# MKE18F16 register map
Vendor: Freescale Semiconductor, Inc.; Series: Kinetis_E; File version: 1.6
CPU: CM4 r0p1, little endian, no MPU, FPU, VTOR, 4 interrupt priority bits
Registers are 32-bit, read-write, reset 0x0 unless marked. A register's access mark holds for its fields unless they carry their own. Offsets are from the block's base; [hi:lo] are bit positions; {n}, {i} and the like mark numbered series; 'fields as' and 'values as' point back to an identical list.

## CAN0 — Flex Controller Area Network module
Base 0x40024000; register names take the prefix CAN0_
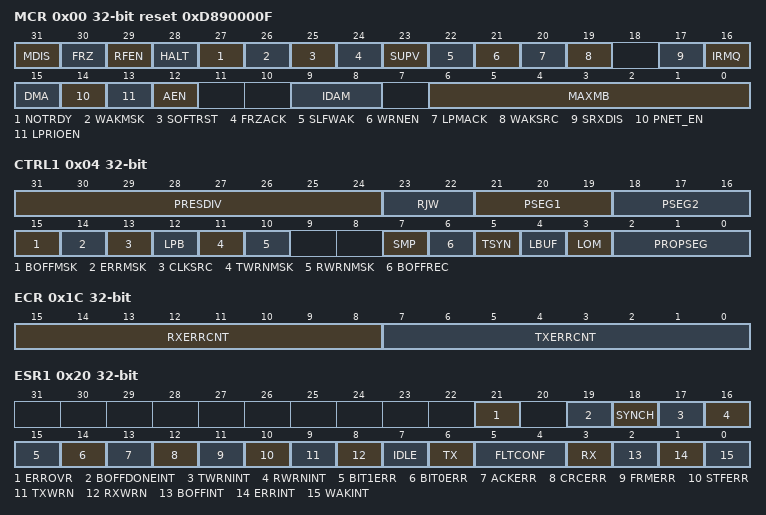
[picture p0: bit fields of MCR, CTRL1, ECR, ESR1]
0x00 MCR reset 0xD890000F — Module Configuration Register
  [31] MDIS — Module Disable
    0=Enable the FlexCAN module; 1=Disable the FlexCAN module
  [30] FRZ — Freeze Enable
    0=Not enabled to enter Freeze mode; 1=Enabled to enter Freeze mode
  [29] RFEN — Rx FIFO Enable
    0=Rx FIFO not enabled; 1=Rx FIFO enabled
  [28] HALT — Halt FlexCAN
    0=No Freeze mode request; 1=Enters Freeze mode if the FRZ bit is asserted
  [27] NOTRDY ro — FlexCAN Not Ready
    0=FlexCAN module is either in Normal mode, Listen-Only mode or Loop-Back mode; 1=FlexCAN module is either in Disable mode, Stop mode or Freeze mode
  [26] WAKMSK — Wake Up Interrupt Mask
    0=Wake Up Interrupt is disabled; 1=Wake Up Interrupt is enabled
  [25] SOFTRST — Soft Reset
    0=No reset request; 1=Resets the registers affected by soft reset
  [24] FRZACK ro — Freeze Mode Acknowledge
    0=FlexCAN not in Freeze mode, prescaler running; 1=FlexCAN in Freeze mode, prescaler stopped
  [23] SUPV — Supervisor Mode
    0=FlexCAN is in User mode. Affected registers allow both Supervisor and Unrestricted accesses.; 1=FlexCAN is in Supervisor mode. Affected registers allow only Supervisor access. Unrestricted access behaves as though the access was done to an unimplemented register location.
  [22] SLFWAK — Self Wake Up
    0=FlexCAN Self Wake Up feature is disabled; 1=FlexCAN Self Wake Up feature is enabled
  [21] WRNEN — Warning Interrupt Enable
    0=TWRNINT and RWRNINT bits are zero, independent of the values in the error counters; 1=TWRNINT and RWRNINT bits are set when the respective error counter transitions from less than 96 to greater than or equal to 96
  [20] LPMACK ro — Low-Power Mode Acknowledge
    0=FlexCAN is not in a low-power mode; 1=FlexCAN is in a low-power mode
  [19] WAKSRC — Wake Up Source
    0=FlexCAN uses the unfiltered Rx input to detect recessive to dominant edges on the CAN bus; 1=FlexCAN uses the filtered Rx input to detect recessive to dominant edges on the CAN bus
  [17] SRXDIS — Self Reception Disable
    0=Self reception enabled; 1=Self reception disabled
  [16] IRMQ — Individual Rx Masking And Queue Enable
    0=Individual Rx masking and queue feature are disabled. For backward compatibility with legacy applications, the reading of C/S word locks the MB even if it is EMPTY.; 1=Individual Rx masking and queue feature are enabled
  [15] DMA — DMA Enable
    0=DMA feature for RX FIFO disabled; 1=DMA feature for RX FIFO enabled
  [14] PNET_EN — Pretended Networking Enable
    0=Pretended Networking mode is disabled; 1=Pretended Networking mode is enabled
  [13] LPRIOEN — Local Priority Enable
    0=Local Priority disabled; 1=Local Priority enabled
  [12] AEN — Abort Enable
    0=Abort disabled; 1=Abort enabled
  [9:8] IDAM — ID Acceptance Mode
    0=Format A: One full ID (standard and extended) per ID Filter Table element; 1=Format B: Two full standard IDs or two partial 14-bit (standard and extended) IDs per ID Filter Table element; 2=Format C: Four partial 8-bit Standard IDs per ID Filter Table element; 3=Format D: All frames rejected
  [6:0] MAXMB — Number Of The Last Message Buffer
0x04 CTRL1 — Control 1 register
  [31:24] PRESDIV — Prescaler Division Factor
  [23:22] RJW — Resync Jump Width
  [21:19] PSEG1 — Phase Segment 1
  [18:16] PSEG2 — Phase Segment 2
  [15] BOFFMSK — Bus Off Interrupt Mask
    0=Bus Off interrupt disabled; 1=Bus Off interrupt enabled
  [14] ERRMSK — Error Interrupt Mask
    0=Error interrupt disabled; 1=Error interrupt enabled
  [13] CLKSRC — CAN Engine Clock Source
    0=The CAN engine clock source is the oscillator clock. Under this condition, the oscillator clock frequency must be lower than the bus clock.; 1=The CAN engine clock source is the peripheral clock
  [12] LPB — Loop Back Mode
    0=Loop Back disabled; 1=Loop Back enabled
  [11] TWRNMSK — Tx Warning Interrupt Mask
    0=Tx Warning Interrupt disabled; 1=Tx Warning Interrupt enabled
  [10] RWRNMSK — Rx Warning Interrupt Mask
    0=Rx Warning Interrupt disabled; 1=Rx Warning Interrupt enabled
  [7] SMP — CAN Bit Sampling
    0=Just one sample is used to determine the bit value; 1=Three samples are used to determine the value of the received bit: the regular one (sample point) and 2 preceding samples; a majority rule is used
  [6] BOFFREC — Bus Off Recovery
    0=Automatic recovering from Bus Off state enabled; 1=Automatic recovering from Bus Off state disabled
  [5] TSYN — Timer Sync
    0=Timer Sync feature disabled; 1=Timer Sync feature enabled
  [4] LBUF — Lowest Buffer Transmitted First
    0=Buffer with highest priority is transmitted first; 1=Lowest number buffer is transmitted first
  [3] LOM — Listen-Only Mode
    0=Listen-Only mode is deactivated; 1=FlexCAN module operates in Listen-Only mode
  [2:0] PROPSEG — Propagation Segment
0x08 TIMER — Free Running Timer
  [15:0] TIMER — Timer Value
0x10 RXMGMASK reset not defined — Rx Mailboxes Global Mask Register
  [31:0] MG — Rx Mailboxes Global Mask Bits
    0=The corresponding bit in the filter is "don't care."; 1=The corresponding bit in the filter is checked
0x14 RX14MASK reset not defined
  [31:0] RX14M — Rx Buffer 14 Mask Bits
    values as RXMGMASK.MG
0x18 RX15MASK reset not defined
  [31:0] RX15M — Rx Buffer 15 Mask Bits
    values as RXMGMASK.MG
0x1C ECR — Error Counter
  [15:8] RXERRCNT — Receive Error Counter
  [7:0] TXERRCNT — Transmit Error Counter
0x20 ESR1 — Error and Status 1 register
  [21] ERROVR — Error Overrun bit
    0=Overrun has not occurred; 1=Overrun has occured
  [19] BOFFDONEINT — Bus Off Done Interrupt
    0=No such occurrence; 1=FlexCAN module has completed Bus Off process
  [18] SYNCH ro — CAN Synchronization Status
    0=FlexCAN is not synchronized to the CAN bus; 1=FlexCAN is synchronized to the CAN bus
  [17] TWRNINT — Tx Warning Interrupt Flag
    0=No such occurrence; 1=The Tx error counter transitioned from less than 96 to greater than or equal to 96
  [16] RWRNINT — Rx Warning Interrupt Flag
    0=No such occurrence; 1=The Rx error counter transitioned from less than 96 to greater than or equal to 96
  [15] BIT1ERR ro — Bit1 Error
    0=No such occurrence; 1=At least one bit sent as recessive is received as dominant
  [14] BIT0ERR ro — Bit0 Error
    0=No such occurrence; 1=At least one bit sent as dominant is received as recessive
  [13] ACKERR ro — Acknowledge Error
    0=No such occurrence; 1=An ACK error occurred since last read of this register
  [12] CRCERR ro — Cyclic Redundancy Check Error
    0=No such occurrence; 1=A CRC error occurred since last read of this register
  [11] FRMERR ro — Form Error
    0=No such occurrence; 1=A Form Error occurred since last read of this register
  [10] STFERR ro — Stuffing Error
    0=No such occurrence; 1=A Stuffing Error occurred since last read of this register
  [9] TXWRN ro — TX Error Warning
    0=No such occurrence; 1=TXERRCNT is greater than or equal to 96
  [8] RXWRN ro — Rx Error Warning
    0=No such occurrence; 1=RXERRCNT is greater than or equal to 96
  [7] IDLE ro — This bit indicates when CAN bus is in IDLE state
    0=No such occurrence; 1=CAN bus is now IDLE
  [6] TX ro — FlexCAN In Transmission
    0=FlexCAN is not transmitting a message; 1=FlexCAN is transmitting a message
  [5:4] FLTCONF ro — Fault Confinement State
    0=Error Active; 1=Error Passive; 0b1x=Bus Off
  [3] RX ro — FlexCAN In Reception
    0=FlexCAN is not receiving a message; 1=FlexCAN is receiving a message
  [2] BOFFINT — Bus Off Interrupt
    0=No such occurrence; 1=FlexCAN module entered Bus Off state
  [1] ERRINT — Error Interrupt
    0=No such occurrence; 1=Indicates setting of any Error Bit in the Error and Status Register
  [0] WAKINT — Wake-Up Interrupt
    0=No such occurrence; 1=Indicates a recessive to dominant transition was received on the CAN bus
0x28 IMASK1 — Interrupt Masks 1 register
  [31:0] BUF31TO0M — Buffer MB i Mask
    0=The corresponding buffer Interrupt is disabled; 1=The corresponding buffer Interrupt is enabled
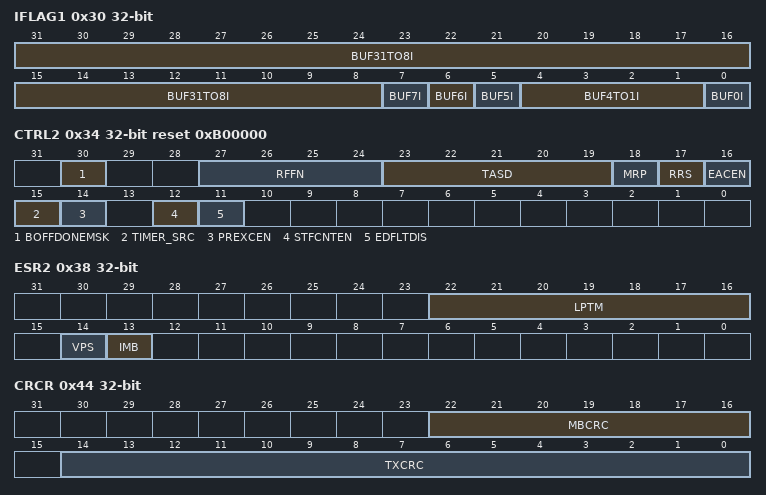
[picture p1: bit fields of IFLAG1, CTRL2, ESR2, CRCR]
0x30 IFLAG1 — Interrupt Flags 1 register
  [31:8] BUF31TO8I — Buffer MBi Interrupt
    0=The corresponding buffer has no occurrence of successfully completed transmission or reception; 1=The corresponding buffer has successfully completed transmission or reception
  [7] BUF7I — Buffer MB7 Interrupt Or "Rx FIFO Overflow"
    0=No occurrence of MB7 completing transmission/reception when MCR[RFEN]=0, or of Rx FIFO overflow when MCR[RFEN]=1; 1=MB7 completed transmission/reception when MCR[RFEN]=0, or Rx FIFO overflow when MCR[RFEN]=1
  [6] BUF6I — Buffer MB6 Interrupt Or "Rx FIFO Warning"
    0=No occurrence of MB6 completing transmission/reception when MCR[RFEN]=0, or of Rx FIFO almost full when MCR[RFEN]=1; 1=MB6 completed transmission/reception when MCR[RFEN]=0, or Rx FIFO almost full when MCR[RFEN]=1
  [5] BUF5I — Buffer MB5 Interrupt Or "Frames available in Rx FIFO"
    0=No occurrence of MB5 completing transmission/reception when MCR[RFEN]=0, or of frame(s) available in the FIFO, when MCR[RFEN]=1; 1=MB5 completed transmission/reception when MCR[RFEN]=0, or frame(s) available in the Rx FIFO when MCR[RFEN]=1. It generates a DMA request in case of MCR[RFEN] and MCR[DMA] are enabled.
  [4:1] BUF4TO1I — Buffer MB i Interrupt Or "reserved"
    0=The corresponding buffer has no occurrence of successfully completed transmission or reception when MCR[RFEN]=0; 1=The corresponding buffer has successfully completed transmission or reception when MCR[RFEN]=0
  [0] BUF0I — Buffer MB0 Interrupt Or Clear FIFO bit
    values as BUF4TO1I
0x34 CTRL2 reset 0xB00000 — Control 2 register
  [30] BOFFDONEMSK — Bus Off Done Interrupt Mask
    0=Bus Off Done interrupt disabled; 1=Bus Off Done interrupt enabled
  [27:24] RFFN — Number Of Rx FIFO Filters
  [23:19] TASD — Tx Arbitration Start Delay
  [18] MRP — Mailboxes Reception Priority
    0=Matching starts from Rx FIFO and continues on Mailboxes; 1=Matching starts from Mailboxes and continues on Rx FIFO
  [17] RRS — Remote Request Storing
    0=Remote Response Frame is generated; 1=Remote Request Frame is stored
  [16] EACEN — Entire Frame Arbitration Field Comparison Enable For Rx Mailboxes
    0=Rx Mailbox filter's IDE bit is always compared and RTR is never compared despite mask bits; 1=Enables the comparison of both Rx Mailbox filter's IDE and RTR bit with their corresponding bits within the incoming frame. Mask bits do apply.
  [15] TIMER_SRC — Timer Source
    0=The Free Running Timer is clocked by the CAN bit clock, which defines the baud rate on the CAN bus; 1=The Free Running Timer is clocked by an external time tick. The period can be either adjusted to be equal to the baud rate on the CAN bus, or a different value as required. See the device specific section for details about the external time tick.
  [14] PREXCEN — Protocol Exception Enable
    0=Protocol Exception is disabled; 1=Protocol Exception is enabled
  [12] STFCNTEN — Stuff Count Enable
    0=Stuff Count feature is disabled. Stuff Count bit field is not inserted before the CRC Sequence field.; 1=Stuff Count feature is enabled. Stuff Count bit field is inserted before the CRC Sequence field.
  [11] EDFLTDIS — Edge Filter Disable
    0=Edge Filter is enabled; 1=Edge Filter is disabled
0x38 ESR2 ro — Error and Status 2 register
  [22:16] LPTM — Lowest Priority Tx Mailbox
  [14] VPS — Valid Priority Status
    0=Contents of IMB and LPTM are invalid; 1=Contents of IMB and LPTM are valid
  [13] IMB — Inactive Mailbox
    0=If ESR2[VPS] is asserted, the ESR2[LPTM] is not an inactive Mailbox; 1=If ESR2[VPS] is asserted, there is at least one inactive Mailbox. LPTM content is the number of the first one.
0x44 CRCR ro — CRC Register
  [22:16] MBCRC — CRC Mailbox
  [14:0] TXCRC — Transmitted CRC value
0x48 RXFGMASK reset not defined — Rx FIFO Global Mask register
  [31:0] FGM — Rx FIFO Global Mask Bits
    values as RXMGMASK.MG
0x4C RXFIR ro reset not defined — Rx FIFO Information Register
  [8:0] IDHIT — Identifier Acceptance Filter Hit Indicator
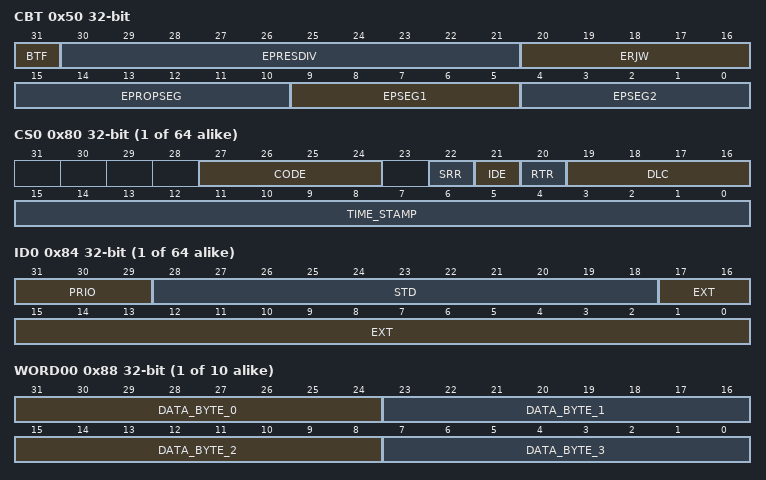
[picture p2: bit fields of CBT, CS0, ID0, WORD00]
0x50 CBT — CAN Bit Timing Register
  [31] BTF — Bit Timing Format Enable
    0=Extended bit time definitions disabled; 1=Extended bit time definitions enabled
  [30:21] EPRESDIV — Extended Prescaler Division Factor
  [20:16] ERJW — Extended Resync Jump Width
  [15:10] EPROPSEG — Extended Propagation Segment
  [9:5] EPSEG1 — Extended Phase Segment 1
  [4:0] EPSEG2 — Extended Phase Segment 2
{0x80+0x10*i} CS{i} (i=0..63) — Message Buffer {i} CS Register
  [27:24] CODE — Reserved
  [22] SRR — Substitute Remote Request. Contains a fixed recessive bit.
  [21] IDE — ID Extended. One/zero for extended/standard format frame.
  [20] RTR — Remote Transmission Request. One/zero for remote/data frame.
  [19:16] DLC — Length of the data to be stored/transmitted.
  [15:0] TIME_STAMP — Free-Running Counter Time stamp. This 16-bit field is a copy of the Free-Running Timer, captured for Tx and Rx frames at the time when the beginning of the Identifier field appears on the CAN bus.
{0x84+0x10*i} ID{i} (i=0..63) — Message Buffer {i} ID Register
  [31:29] PRIO — Local priority. This 3-bit fieldis only used when LPRIO_EN bit is set in MCR and it only makes sense for Tx buffers. These bits are not transmitted. They are appended to the regular ID to define the transmission priority.
  [28:18] STD — Contains standard/extended (HIGH word) identifier of message buffer.
  [17:0] EXT — Contains extended (LOW word) identifier of message buffer.
{0x88+0x10*i} WORD{i:02} (i=0..9) — Message Buffer {i} WORD0 Register
  [31-8n:24-8n] DATA_BYTE_{n} (n=0..3) — Data byte {n} of Rx/Tx frame.
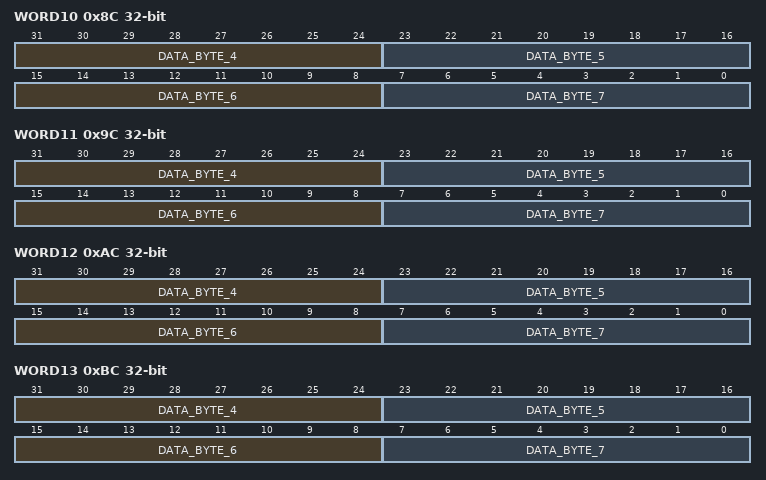
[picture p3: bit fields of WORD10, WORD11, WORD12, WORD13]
0x8C WORD10 — Message Buffer 0 WORD1 Register
  [63-8n:56-8n] DATA_BYTE_{n} (n=4..7) — Data byte {n} of Rx/Tx frame.
0x9C WORD11 — Message Buffer 1 WORD1 Register
  [63-8n:56-8n] DATA_BYTE_{n} (n=4..7) — Data byte {n} of Rx/Tx frame.
0xAC WORD12 — Message Buffer 2 WORD1 Register
  [63-8n:56-8n] DATA_BYTE_{n} (n=4..7) — Data byte {n} of Rx/Tx frame.
0xBC WORD13 — Message Buffer 3 WORD1 Register
  [63-8n:56-8n] DATA_BYTE_{n} (n=4..7) — Data byte {n} of Rx/Tx frame.
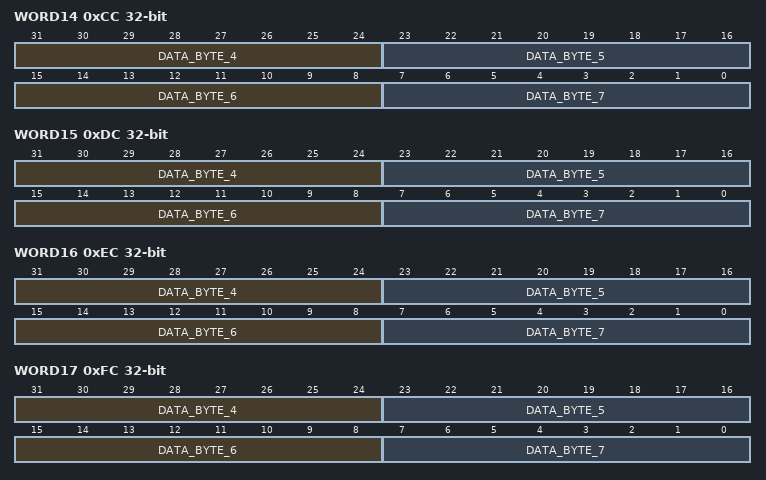
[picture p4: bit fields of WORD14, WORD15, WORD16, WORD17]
0xCC WORD14 — Message Buffer 4 WORD1 Register
  [63-8n:56-8n] DATA_BYTE_{n} (n=4..7) — Data byte {n} of Rx/Tx frame.
0xDC WORD15 — Message Buffer 5 WORD1 Register
  [63-8n:56-8n] DATA_BYTE_{n} (n=4..7) — Data byte {n} of Rx/Tx frame.
0xEC WORD16 — Message Buffer 6 WORD1 Register
  [63-8n:56-8n] DATA_BYTE_{n} (n=4..7) — Data byte {n} of Rx/Tx frame.
0xFC WORD17 — Message Buffer 7 WORD1 Register
  [63-8n:56-8n] DATA_BYTE_{n} (n=4..7) — Data byte {n} of Rx/Tx frame.
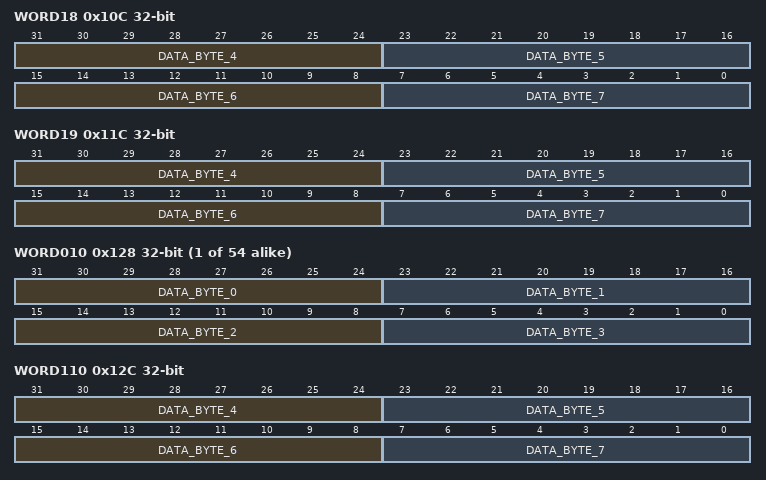
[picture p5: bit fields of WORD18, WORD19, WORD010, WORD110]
0x10C WORD18 — Message Buffer 8 WORD1 Register
  [63-8n:56-8n] DATA_BYTE_{n} (n=4..7) — Data byte {n} of Rx/Tx frame.
0x11C WORD19 — Message Buffer 9 WORD1 Register
  [63-8n:56-8n] DATA_BYTE_{n} (n=4..7) — Data byte {n} of Rx/Tx frame.
{0x88+0x10*i} WORD{i:03} (i=10..63) — Message Buffer {i} WORD0 Register
  [31-8n:24-8n] DATA_BYTE_{n} (n=0..3) — Data byte {n} of Rx/Tx frame.
0x12C WORD110 — Message Buffer 10 WORD1 Register
  [63-8n:56-8n] DATA_BYTE_{n} (n=4..7) — Data byte {n} of Rx/Tx frame.
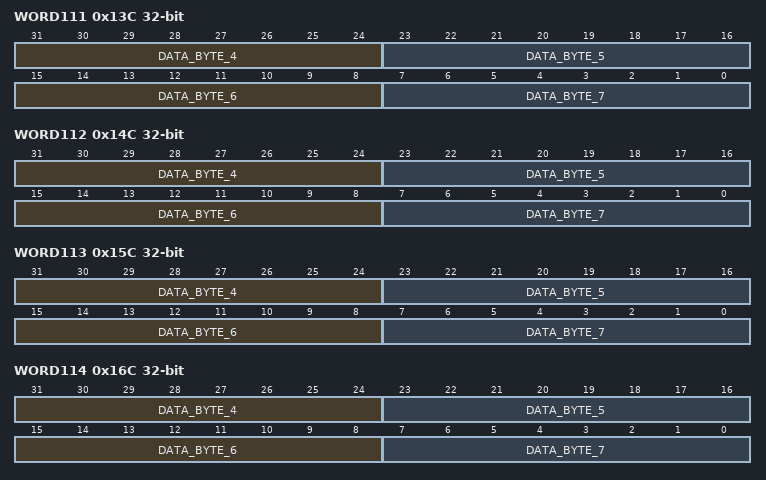
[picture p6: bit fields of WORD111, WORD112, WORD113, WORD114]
0x13C WORD111 — Message Buffer 11 WORD1 Register
  [63-8n:56-8n] DATA_BYTE_{n} (n=4..7) — Data byte {n} of Rx/Tx frame.
0x14C WORD112 — Message Buffer 12 WORD1 Register
  [63-8n:56-8n] DATA_BYTE_{n} (n=4..7) — Data byte {n} of Rx/Tx frame.
0x15C WORD113 — Message Buffer 13 WORD1 Register
  [63-8n:56-8n] DATA_BYTE_{n} (n=4..7) — Data byte {n} of Rx/Tx frame.
0x16C WORD114 — Message Buffer 14 WORD1 Register
  [63-8n:56-8n] DATA_BYTE_{n} (n=4..7) — Data byte {n} of Rx/Tx frame.
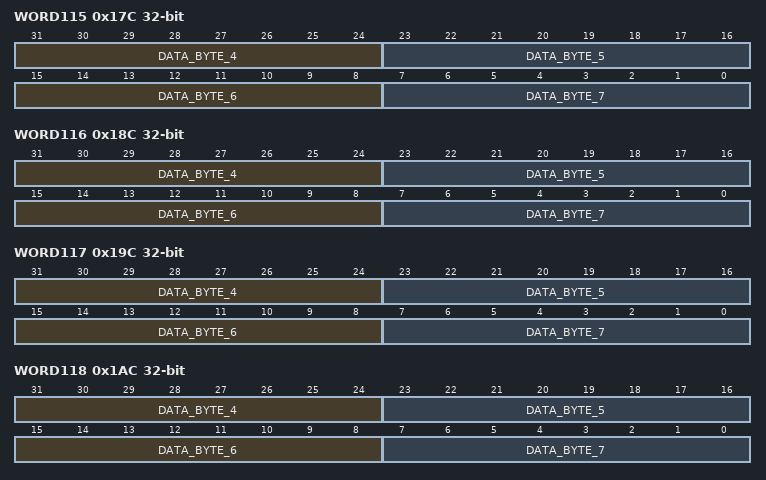
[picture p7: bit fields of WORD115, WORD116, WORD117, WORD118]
0x17C WORD115 — Message Buffer 15 WORD1 Register
  [63-8n:56-8n] DATA_BYTE_{n} (n=4..7) — Data byte {n} of Rx/Tx frame.
0x18C WORD116 — Message Buffer 16 WORD1 Register
  [63-8n:56-8n] DATA_BYTE_{n} (n=4..7) — Data byte {n} of Rx/Tx frame.
0x19C WORD117 — Message Buffer 17 WORD1 Register
  [63-8n:56-8n] DATA_BYTE_{n} (n=4..7) — Data byte {n} of Rx/Tx frame.
0x1AC WORD118 — Message Buffer 18 WORD1 Register
  [63-8n:56-8n] DATA_BYTE_{n} (n=4..7) — Data byte {n} of Rx/Tx frame.
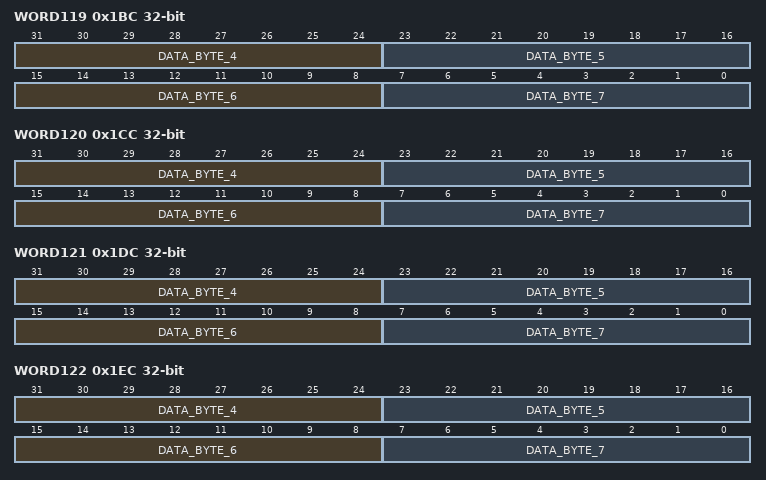
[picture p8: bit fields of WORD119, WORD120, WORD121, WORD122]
0x1BC WORD119 — Message Buffer 19 WORD1 Register
  [63-8n:56-8n] DATA_BYTE_{n} (n=4..7) — Data byte {n} of Rx/Tx frame.
0x1CC WORD120 — Message Buffer 20 WORD1 Register
  [63-8n:56-8n] DATA_BYTE_{n} (n=4..7) — Data byte {n} of Rx/Tx frame.
0x1DC WORD121 — Message Buffer 21 WORD1 Register
  [63-8n:56-8n] DATA_BYTE_{n} (n=4..7) — Data byte {n} of Rx/Tx frame.
0x1EC WORD122 — Message Buffer 22 WORD1 Register
  [63-8n:56-8n] DATA_BYTE_{n} (n=4..7) — Data byte {n} of Rx/Tx frame.
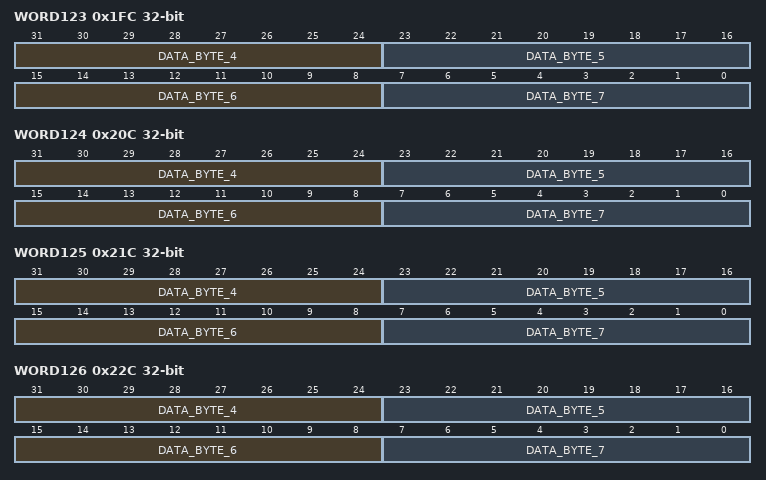
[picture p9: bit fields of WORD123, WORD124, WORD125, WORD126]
0x1FC WORD123 — Message Buffer 23 WORD1 Register
  [63-8n:56-8n] DATA_BYTE_{n} (n=4..7) — Data byte {n} of Rx/Tx frame.
0x20C WORD124 — Message Buffer 24 WORD1 Register
  [63-8n:56-8n] DATA_BYTE_{n} (n=4..7) — Data byte {n} of Rx/Tx frame.
0x21C WORD125 — Message Buffer 25 WORD1 Register
  [63-8n:56-8n] DATA_BYTE_{n} (n=4..7) — Data byte {n} of Rx/Tx frame.
0x22C WORD126 — Message Buffer 26 WORD1 Register
  [63-8n:56-8n] DATA_BYTE_{n} (n=4..7) — Data byte {n} of Rx/Tx frame.
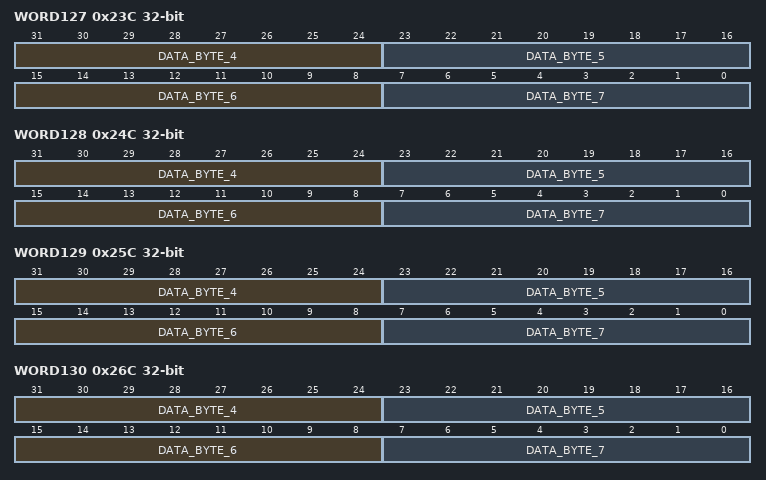
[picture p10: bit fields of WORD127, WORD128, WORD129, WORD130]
0x23C WORD127 — Message Buffer 27 WORD1 Register
  [63-8n:56-8n] DATA_BYTE_{n} (n=4..7) — Data byte {n} of Rx/Tx frame.
0x24C WORD128 — Message Buffer 28 WORD1 Register
  [63-8n:56-8n] DATA_BYTE_{n} (n=4..7) — Data byte {n} of Rx/Tx frame.
0x25C WORD129 — Message Buffer 29 WORD1 Register
  [63-8n:56-8n] DATA_BYTE_{n} (n=4..7) — Data byte {n} of Rx/Tx frame.
0x26C WORD130 — Message Buffer 30 WORD1 Register
  [63-8n:56-8n] DATA_BYTE_{n} (n=4..7) — Data byte {n} of Rx/Tx frame.
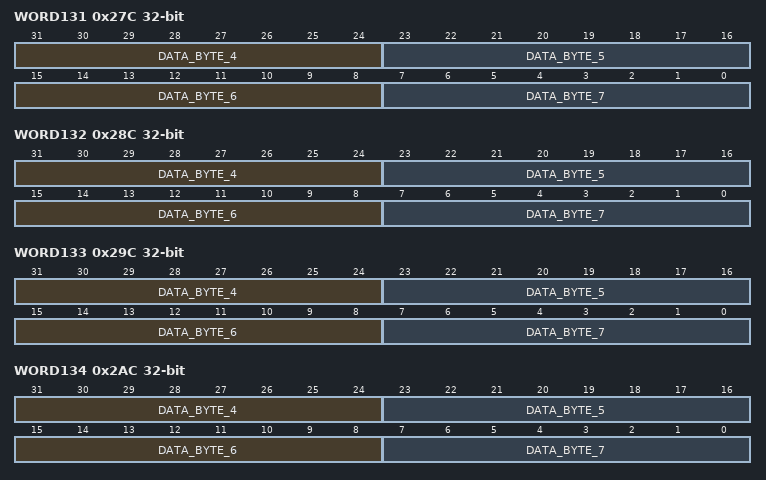
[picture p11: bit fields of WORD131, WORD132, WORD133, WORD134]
0x27C WORD131 — Message Buffer 31 WORD1 Register
  [63-8n:56-8n] DATA_BYTE_{n} (n=4..7) — Data byte {n} of Rx/Tx frame.
0x28C WORD132 — Message Buffer 32 WORD1 Register
  [63-8n:56-8n] DATA_BYTE_{n} (n=4..7) — Data byte {n} of Rx/Tx frame.
0x29C WORD133 — Message Buffer 33 WORD1 Register
  [63-8n:56-8n] DATA_BYTE_{n} (n=4..7) — Data byte {n} of Rx/Tx frame.
0x2AC WORD134 — Message Buffer 34 WORD1 Register
  [63-8n:56-8n] DATA_BYTE_{n} (n=4..7) — Data byte {n} of Rx/Tx frame.
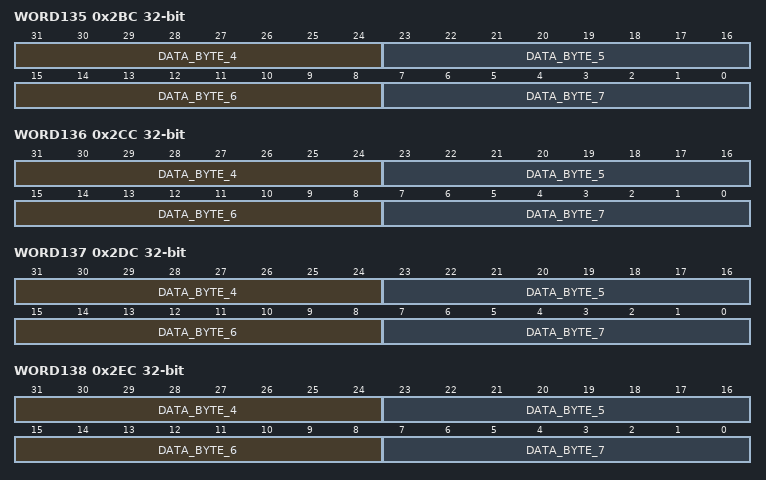
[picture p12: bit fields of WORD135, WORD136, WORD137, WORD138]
0x2BC WORD135 — Message Buffer 35 WORD1 Register
  [63-8n:56-8n] DATA_BYTE_{n} (n=4..7) — Data byte {n} of Rx/Tx frame.
0x2CC WORD136 — Message Buffer 36 WORD1 Register
  [63-8n:56-8n] DATA_BYTE_{n} (n=4..7) — Data byte {n} of Rx/Tx frame.
0x2DC WORD137 — Message Buffer 37 WORD1 Register
  [63-8n:56-8n] DATA_BYTE_{n} (n=4..7) — Data byte {n} of Rx/Tx frame.
0x2EC WORD138 — Message Buffer 38 WORD1 Register
  [63-8n:56-8n] DATA_BYTE_{n} (n=4..7) — Data byte {n} of Rx/Tx frame.
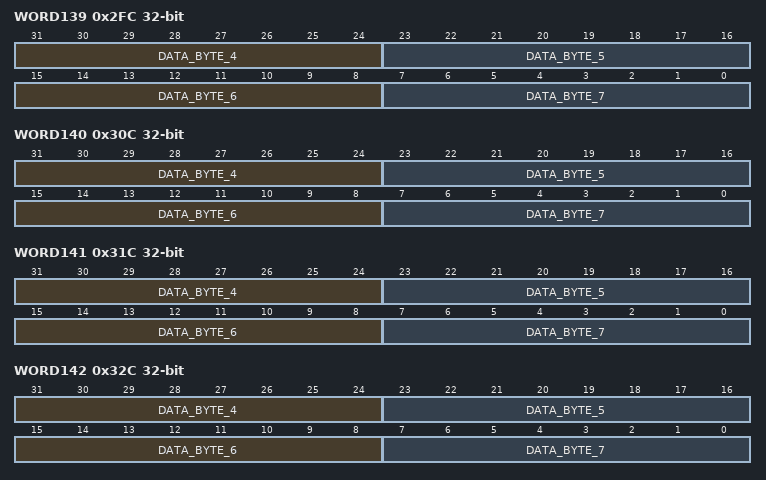
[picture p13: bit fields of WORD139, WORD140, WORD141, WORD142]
0x2FC WORD139 — Message Buffer 39 WORD1 Register
  [63-8n:56-8n] DATA_BYTE_{n} (n=4..7) — Data byte {n} of Rx/Tx frame.
0x30C WORD140 — Message Buffer 40 WORD1 Register
  [63-8n:56-8n] DATA_BYTE_{n} (n=4..7) — Data byte {n} of Rx/Tx frame.
0x31C WORD141 — Message Buffer 41 WORD1 Register
  [63-8n:56-8n] DATA_BYTE_{n} (n=4..7) — Data byte {n} of Rx/Tx frame.
0x32C WORD142 — Message Buffer 42 WORD1 Register
  [63-8n:56-8n] DATA_BYTE_{n} (n=4..7) — Data byte {n} of Rx/Tx frame.
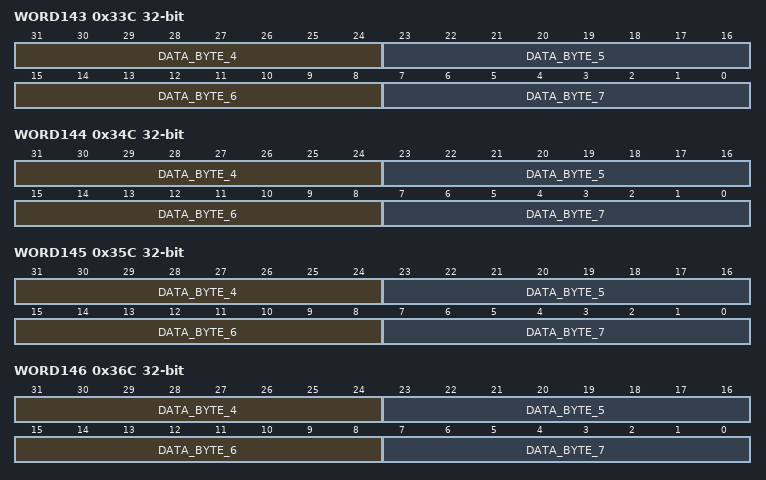
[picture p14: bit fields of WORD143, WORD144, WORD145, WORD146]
0x33C WORD143 — Message Buffer 43 WORD1 Register
  [63-8n:56-8n] DATA_BYTE_{n} (n=4..7) — Data byte {n} of Rx/Tx frame.
0x34C WORD144 — Message Buffer 44 WORD1 Register
  [63-8n:56-8n] DATA_BYTE_{n} (n=4..7) — Data byte {n} of Rx/Tx frame.
0x35C WORD145 — Message Buffer 45 WORD1 Register
  [63-8n:56-8n] DATA_BYTE_{n} (n=4..7) — Data byte {n} of Rx/Tx frame.
0x36C WORD146 — Message Buffer 46 WORD1 Register
  [63-8n:56-8n] DATA_BYTE_{n} (n=4..7) — Data byte {n} of Rx/Tx frame.
0x37C WORD147 — Message Buffer 47 WORD1 Register
  [63-8n:56-8n] DATA_BYTE_{n} (n=4..7) — Data byte {n} of Rx/Tx frame.
0x38C WORD148 — Message Buffer 48 WORD1 Register
  [63-8n:56-8n] DATA_BYTE_{n} (n=4..7) — Data byte {n} of Rx/Tx frame.
0x39C WORD149 — Message Buffer 49 WORD1 Register
  [63-8n:56-8n] DATA_BYTE_{n} (n=4..7) — Data byte {n} of Rx/Tx frame.
0x3AC WORD150 — Message Buffer 50 WORD1 Register
  [63-8n:56-8n] DATA_BYTE_{n} (n=4..7) — Data byte {n} of Rx/Tx frame.
0x3BC WORD151 — Message Buffer 51 WORD1 Register
  [63-8n:56-8n] DATA_BYTE_{n} (n=4..7) — Data byte {n} of Rx/Tx frame.
0x3CC WORD152 — Message Buffer 52 WORD1 Register
  [63-8n:56-8n] DATA_BYTE_{n} (n=4..7) — Data byte {n} of Rx/Tx frame.
0x3DC WORD153 — Message Buffer 53 WORD1 Register
  [63-8n:56-8n] DATA_BYTE_{n} (n=4..7) — Data byte {n} of Rx/Tx frame.
0x3EC WORD154 — Message Buffer 54 WORD1 Register
  [63-8n:56-8n] DATA_BYTE_{n} (n=4..7) — Data byte {n} of Rx/Tx frame.
0x3FC WORD155 — Message Buffer 55 WORD1 Register
  [63-8n:56-8n] DATA_BYTE_{n} (n=4..7) — Data byte {n} of Rx/Tx frame.
0x40C WORD156 — Message Buffer 56 WORD1 Register
  [63-8n:56-8n] DATA_BYTE_{n} (n=4..7) — Data byte {n} of Rx/Tx frame.
0x41C WORD157 — Message Buffer 57 WORD1 Register
  [63-8n:56-8n] DATA_BYTE_{n} (n=4..7) — Data byte {n} of Rx/Tx frame.
0x42C WORD158 — Message Buffer 58 WORD1 Register
  [63-8n:56-8n] DATA_BYTE_{n} (n=4..7) — Data byte {n} of Rx/Tx frame.
0x43C WORD159 — Message Buffer 59 WORD1 Register
  [63-8n:56-8n] DATA_BYTE_{n} (n=4..7) — Data byte {n} of Rx/Tx frame.
0x44C WORD160 — Message Buffer 60 WORD1 Register
  [63-8n:56-8n] DATA_BYTE_{n} (n=4..7) — Data byte {n} of Rx/Tx frame.
0x45C WORD161 — Message Buffer 61 WORD1 Register
  [63-8n:56-8n] DATA_BYTE_{n} (n=4..7) — Data byte {n} of Rx/Tx frame.
0x46C WORD162 — Message Buffer 62 WORD1 Register
  [63-8n:56-8n] DATA_BYTE_{n} (n=4..7) — Data byte {n} of Rx/Tx frame.
0x47C WORD163 — Message Buffer 63 WORD1 Register
  [63-8n:56-8n] DATA_BYTE_{n} (n=4..7) — Data byte {n} of Rx/Tx frame.
{0x880+4i} RXIMR{i} (i=0..15) reset not defined — Rx Individual Mask Registers
  [31:0] MI — Individual Mask Bits
    values as RXMGMASK.MG
0xB00 CTRL1_PN reset 0x100 — Pretended Networking Control 1 Register
  [17] WTOF_MSK — Wake Up by Timeout Flag Mask Bit
    0=Timeout wake up event is disabled; 1=Timeout wake up event is enabled
  [16] WUMF_MSK — Wake Up by Match Flag Mask Bit
    0=Wake up match event is disabled; 1=Wake up match event is enabled
  [15:8] NMATCH — Number of Messages Matching the Same Filtering Criteria
    1=Received message must match the predefined filtering criteria for ID and/or PL once before generating a wake up event; 2=Received message must match the predefined filtering criteria for ID and/or PL twice before generating a wake up event; 255=Received message must match the predefined filtering criteria for ID and/or PL 255 times before generating a wake up event
  [5:4] PLFS — Payload Filtering Selection
    0=Match upon a payload contents against an exact target value; 1=Match upon a payload value greater than or equal to a specified target value; 2=Match upon a payload value smaller than or equal to a specified target value; 3=Match upon a payload value inside a range, greater than or equal to a specified lower limit and smaller than or equal a specified upper limit
  [3:2] IDFS — ID Filtering Selection
    0=Match upon a ID contents against an exact target value; 1=Match upon a ID value greater than or equal to a specified target value; 2=Match upon a ID value smaller than or equal to a specified target value; 3=Match upon a ID value inside a range, greater than or equal to a specified lower limit and smaller than or equal a specified upper limit
  [1:0] FCS — Filtering Combination Selection
    0=Message ID filtering only; 1=Message ID filtering and payload filtering; 2=Message ID filtering occurring a specified number of times; 3=Message ID filtering and payload filtering a specified number of times
0xB04 CTRL2_PN — Pretended Networking Control 2 Register
  [15:0] MATCHTO — Timeout for No Message Matching the Filtering Criteria
0xB08 WU_MTC — Pretended Networking Wake Up Match Register
  [17] WTOF — Wake Up by Timeout Flag Bit
    0=No wake up by timeout event detected; 1=Wake up by timeout event detected
  [16] WUMF — Wake Up by Match Flag Bit
    0=No wake up by match event detected; 1=Wake up by match event detected
  [15:8] MCOUNTER ro — Number of Matches while in Pretended Networking
0xB0C FLT_ID1 — Pretended Networking ID Filter 1 Register
  [30] FLT_IDE — ID Extended Filter
    0=Accept standard frame format; 1=Accept extended frame format
  [29] FLT_RTR — Remote Transmission Request Filter
    0=Reject remote frame (accept data frame); 1=Accept remote frame
  [28:0] FLT_ID1 — ID Filter 1 for Pretended Networking filtering
0xB10 FLT_DLC reset 0x8 — Pretended Networking DLC Filter Register
  [19:16] FLT_DLC_LO — Lower Limit for Length of Data Bytes Filter
  [3:0] FLT_DLC_HI — Upper Limit for Length of Data Bytes Filter
0xB14 PL1_LO — Pretended Networking Payload Low Filter 1 Register
  [31-8n:24-8n] Data_byte_{n} (n=0..3) — Payload Filter 1 low order bits for Pretended Networking payload filtering corresponding to the data byte {n}.
0xB18 PL1_HI — Pretended Networking Payload High Filter 1 Register
  [63-8n:56-8n] Data_byte_{n} (n=4..7) — Payload Filter 1 high order bits for Pretended Networking payload filtering corresponding to the data byte {n}.
0xB1C FLT_ID2_IDMASK — Pretended Networking ID Filter 2 Register / ID Mask Register
  [30] IDE_MSK — ID Extended Mask Bit
    0=The corresponding bit in the filter is "don't care"; 1=The corresponding bit in the filter is checked
  [29] RTR_MSK — Remote Transmission Request Mask Bit
    values as IDE_MSK
  [28:0] FLT_ID2_IDMASK — ID Filter 2 for Pretended Networking Filtering / ID Mask Bits for Pretended Networking ID Filtering
0xB20 PL2_PLMASK_LO — Pretended Networking Payload Low Filter 2 Register / Payload Low Mask Register
  [31-8n:24-8n] Data_byte_{n} (n=0..3) — Payload Filter 2 low order bits / Payload Mask low order bits for Pretended Networking payload filtering corresponding to the data byte {n}.
0xB24 PL2_PLMASK_HI — Pretended Networking Payload High Filter 2 low order bits / Payload High Mask Register
  [63-8n:56-8n] Data_byte_{n} (n=4..7) — Payload Filter 2 high order bits / Payload Mask high order bits for Pretended Networking payload filtering corresponding to the data byte {n}.
{0xB40+0x10*i} WMB{i}_CS (i=0..3) ro — Wake Up Message Buffer Register for C/S
  [22] SRR — Substitute Remote Request
  [21] IDE — ID Extended Bit
    0=Frame format is standard; 1=Frame format is extended
  [20] RTR — Remote Transmission Request Bit
    0=Frame is data one (not remote); 1=Frame is a remote one
  [19:16] DLC — Length of Data in Bytes
{0xB44+0x10*i} WMB{i}_ID (i=0..3) ro — Wake Up Message Buffer Register for ID
  [28:0] ID — Received ID under Pretended Networking mode
{0xB48+0x10*i} WMB{i}_D03 (i=0..3) ro — Wake Up Message Buffer Register for Data 0-3
  [31-8n:24-8n] Data_byte_{n} (n=0..3) — Received payload corresponding to the data byte {n} under Pretended Networking mode
{0xB4C+0x10*i} WMB{i}_D47 (i=0..3) ro — Wake Up Message Buffer Register Data 4-7
  [63-8n:56-8n] Data_byte_{n} (n=4..7) — Received payload corresponding to the data byte {n} under Pretended Networking mode

## CAN1 — Flex Controller Area Network module
Base 0x40025000; register names take the prefix CAN1_
Registers as CAN0.
